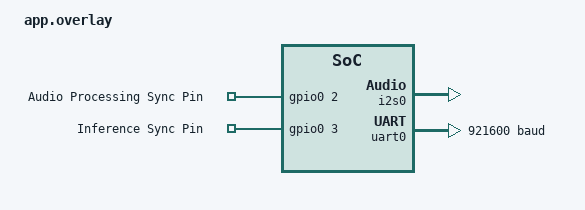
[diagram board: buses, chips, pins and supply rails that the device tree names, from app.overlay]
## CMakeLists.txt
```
# Copyright (c) 2026 Seeed Studio / Senior ML Engineer
# SPDX-License-Identifier: Apache-2.0

cmake_minimum_required(VERSION 3.20.0)

# Find Zephyr package
find_package(Zephyr REQUIRED HINTS $ENV{ZEPHYR_BASE})
project(esc50_zephyr)

# Include esp-dl path (located in /home/acar/streamable-kws/esp-dl)
if(NOT DEFINED ESPDL_PATH)
    set(ESPDL_PATH ${CMAKE_CURRENT_SOURCE_DIR}/../../../streamable-kws/esp-dl/esp-dl)
    if(NOT EXISTS ${ESPDL_PATH})
        set(ESPDL_PATH /home/acar/streamable-kws/esp-dl/esp-dl)
    endif()
endif()

if(NOT DEFINED DL_FFT_PATH)
    set(DL_FFT_PATH ${CMAKE_CURRENT_SOURCE_DIR}/../../../streamable-kws/esp-dl/tools/dl_fft)
    if(NOT EXISTS ${DL_FFT_PATH})
        set(DL_FFT_PATH /home/acar/streamable-kws/esp-dl/tools/dl_fft)
    endif()
endif()

# ============================================================
# ESP-IDF HAL Paths (for PDM support)
# ============================================================
if(NOT DEFINED ESP_HAL_PATH)
    set(ESP_HAL_PATH ${CMAKE_CURRENT_SOURCE_DIR}/../../../zephyrproject/modules/hal/espressif)
    if(NOT EXISTS ${ESP_HAL_PATH})
        set(ESP_HAL_PATH /home/acar/zephyrproject/modules/hal/espressif)
    endif()
endif()

target_include_directories(app PRIVATE
    src/compat
    ${ESPDL_PATH}/dl
    ${ESPDL_PATH}/dl/tool/include
    ${ESPDL_PATH}/dl/tensor/include
    ${ESPDL_PATH}/dl/base
    ${ESPDL_PATH}/dl/base/isa
    ${ESPDL_PATH}/dl/base/isa/tie728
    ${ESPDL_PATH}/dl/base/isa/xtensa
    ${ESPDL_PATH}/dl/math/include
    ${ESPDL_PATH}/dl/model/include
    ${ESPDL_PATH}/dl/module/include
    ${ESPDL_PATH}/fbs_loader/include
    ${ESPDL_PATH}/audio/common
    ${ESPDL_PATH}/audio/speech_features
    ${DL_FFT_PATH}
    ${DL_FFT_PATH}/base
    ${DL_FFT_PATH}/base/isa
    ${CMAKE_CURRENT_BINARY_DIR}
    src
    # ESP-IDF HAL includes - CORRECTED PATHS
    ${ESP_HAL_PATH}/components/esp_hal_i2s/include/hal
    ${ESP_HAL_PATH}/components/esp_common/include
    ${ESP_HAL_PATH}/components/driver/include
    ${ESP_HAL_PATH}/components/esp_hw_support/include
    ${ESP_HAL_PATH}/components/esp_hw_support/include/soc
    ${ESP_HAL_PATH}/components/soc/esp32s3/include
    ${ESP_HAL_PATH}/components/soc/include
    ${ESP_HAL_PATH}/components/esp_rom/include
    ${ESP_HAL_PATH}/components/esp_rom/include/esp32s3
    ${ESP_HAL_PATH}/components/esp_private/include
    ${ESP_HAL_PATH}/components/esp_hal_i2s/include
)

target_compile_definitions(app PRIVATE
    _USE_MATH_DEFINES
    _GNU_SOURCE
    M_PI=3.14159265358979323846
    # ESP-IDF definitions for HAL
    ESP_PLATFORM=1
    SOC_ESP32S3=1
    CONFIG_IDF_TARGET_ESP32S3=1
    CONFIG_SPIRAM=1
)

file(GLOB ESPDL_SRCS
    ${ESPDL_PATH}/dl/tool/src/*.cpp
    ${ESPDL_PATH}/dl/tool/isa/tie728/*.S
    ${ESPDL_PATH}/dl/tool/isa/xtensa/*.S
    ${ESPDL_PATH}/dl/tensor/src/*.cpp
    ${ESPDL_PATH}/dl/base/*.cpp
    ${ESPDL_PATH}/dl/base/isa/tie728/*.S
    ${ESPDL_PATH}/dl/base/isa/xtensa/*.S
    ${ESPDL_PATH}/dl/math/src/*.cpp
    ${ESPDL_PATH}/dl/model/src/*.cpp
    ${ESPDL_PATH}/dl/module/src/*.cpp
    ${ESPDL_PATH}/fbs_loader/src/*.cpp
    ${ESPDL_PATH}/audio/common/*.cpp
    ${ESPDL_PATH}/audio/speech_features/*.cpp
    ${DL_FFT_PATH}/*.c
    ${DL_FFT_PATH}/base/*.c
    ${DL_FFT_PATH}/base/isa/esp32s3/*.S
)

target_sources(app PRIVATE 
    src/main.cpp 
    src/audio.cpp
    src/audio_preprocessing.cpp
    src/inference.cpp
    src/compat/posix_stubs.c
    src/compat/esp_heap_caps.cpp 
    ${ESPDL_SRCS}
)

# Link ESP-IDF HAL library if available
target_link_libraries(app PRIVATE 
    ${ESPDL_PATH}/fbs_loader/lib/esp32s3/libfbs_model.a
    "-Wl,--wrap=heap_caps_malloc"
    "-Wl,--wrap=heap_caps_free"
    "-Wl,--wrap=heap_caps_realloc"
    "-Wl,--wrap=heap_caps_calloc"
    "-Wl,--wrap=heap_caps_aligned_alloc"
    "-Wl,--wrap=heap_caps_aligned_free"
    "-Wl,--wrap=heap_caps_aligned_calloc"
    "-Wl,--wrap=heap_caps_get_free_size"
    "-Wl,--wrap=heap_caps_get_largest_free_block"
    "-Wl,--wrap=heap_caps_get_allocated_size"
    "-Wl,--wrap=heap_caps_get_total_size"
    "-Wl,--wrap=heap_caps_get_minimum_free_size"
    "-Wl,--wrap=heap_caps_get_info"
    "-Wl,--wrap=heap_caps_malloc_default"
    "-Wl,--wrap=heap_caps_realloc_default"
    "-Wl,--wrap=heap_caps_malloc_prefer"
    "-Wl,--wrap=heap_caps_realloc_prefer"
    "-Wl,--wrap=heap_caps_calloc_prefer"
    "-Wl,--wrap=heap_caps_register_failed_alloc_callback"
    "-Wl,--wrap=heap_caps_malloc_extmem_enable"
    "-Wl,--wrap=heap_caps_print_heap_info"
    "-Wl,--wrap=heap_caps_check_integrity"
    "-Wl,--wrap=heap_caps_check_integrity_all"
    "-Wl,--wrap=heap_caps_check_integrity_addr"
    "-Wl,--wrap=heap_caps_dump"
    "-Wl,--wrap=heap_caps_dump_all"
    "-Wl,--wrap=malloc"
    "-Wl,--wrap=free"
    "-Wl,--wrap=calloc"
    "-Wl,--wrap=realloc"
)

# Try to link ESP-IDF HAL libraries if they exist
if(EXISTS ${ESP_HAL_PATH}/components/esp_common/lib/esp32s3/libesp_common.a)
    target_link_libraries(app PRIVATE 
        ${ESP_HAL_PATH}/components/esp_common/lib/esp32s3/libesp_common.a
    )
endif()

if(EXISTS ${ESP_HAL_PATH}/components/driver/lib/esp32s3/libdriver.a)
    target_link_libraries(app PRIVATE 
        ${ESP_HAL_PATH}/components/driver/lib/esp32s3/libdriver.a
    )
endif()

generate_inc_file_for_target(app src/model.espdl ${CMAKE_CURRENT_BINARY_DIR}/model_espdl.inc)
```

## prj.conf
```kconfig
# C++ Support
CONFIG_CPP=y
CONFIG_STD_CPP20=y
CONFIG_REQUIRES_FULL_LIBCPP=y
CONFIG_NEWLIB_LIBC=y
# FPU Support
CONFIG_FPU=y
CONFIG_FPU_SHARING=y

# ESP32-S3 PSRAM - Use PSRAM for large allocations!
CONFIG_ESP_SPIRAM=y
CONFIG_SPIRAM_MODE_OCT=y
CONFIG_ESP_SPIRAM_HEAP_SIZE=4194304

# Memory - Optimized for DRAM (64 KB Heap for Slim TCN RODATA execution)
CONFIG_HEAP_MEM_POOL_SIZE=65536
CONFIG_MAIN_STACK_SIZE=8192
CONFIG_SYSTEM_WORKQUEUE_STACK_SIZE=4096
CONFIG_IDLE_STACK_SIZE=2048
CONFIG_ISR_STACK_SIZE=4096

# Logging
CONFIG_LOG=y
CONFIG_LOG_DEFAULT_LEVEL=3
CONFIG_LOG_MODE_IMMEDIATE=y
CONFIG_LOG_BUFFER_SIZE=4096
CONFIG_SERIAL=y
CONFIG_CONSOLE=y
CONFIG_UART_CONSOLE=y

# GPIO
CONFIG_GPIO=y

# I2S
CONFIG_I2S=y
CONFIG_I2S_ESP32=y
CONFIG_I2S_ESP32_RX_BLOCK_COUNT=16
CONFIG_DMA=y
CONFIG_DMA_ESP32=y

# Ring buffer
CONFIG_RING_BUFFER_LARGE=y

# Disable unnecessary features to save RAM
CONFIG_DEBUG_THREAD_INFO=n
CONFIG_THREAD_STACK_INFO=n
CONFIG_STACK_SENTINEL=n

# Speed Optimizations (Compile with -O2)
CONFIG_SPEED_OPTIMIZATIONS=y

# Disable Bluetooth to maximize free RAM & CPU performance
CONFIG_BT=n

# CPU Clock Frequency (240 MHz Max Speed)
CONFIG_SYS_CLOCK_HW_CYCLES_PER_SEC=240000000
```

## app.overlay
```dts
/*
 * Device Tree Overlay for Seeed Studio XIAO ESP32-S3 Sense
 * I2S Microphone Pin Configuration (3-wire I2S RX Stream: BCK, SD, WS)
 */

#include <zephyr/dt-bindings/pinctrl/esp32s3-pinctrl.h>

/ {
	aliases {
		i2s-mic = &i2s0;
		sync-ap = &sync_ap_pin;
		sync-inf = &sync_inf_pin;
	};
	chosen {
		/delete-property/ zephyr,camera;
	};

	debug_pins {
		compatible = "gpio-keys";
		sync_ap_pin: sync_ap_pin {
			gpios = <&gpio0 2 GPIO_ACTIVE_HIGH>; /* GPIO2 (Pin D1) */
			label = "Audio Processing Sync Pin";
		};
		sync_inf_pin: sync_inf_pin {
			gpios = <&gpio0 3 GPIO_ACTIVE_HIGH>; /* GPIO3 (Pin D2) */
			label = "Inference Sync Pin";
		};
	};
};

&i2c1 {
	status = "disabled";
};

&lcd_cam {
	status = "disabled";
};

&lcd_cam_dvp {
	status = "disabled";
};


&pinctrl {
	i2s0_default: i2s0_default {
		group1 {
			pinmux =
				 <I2S0_I_WS_GPIO42>,
				 <I2S0_I_SD_GPIO41>;
		};
	};
};

&i2s0 {
	status = "okay";
	pinctrl-0 = <&i2s0_default>;
	pinctrl-names = "default";
};

&uart0 {
	status = "okay";
	current-speed = <921600>;
};

&cpu0 {
	clock-frequency = <160000000>;
};

&cpu1 {
	clock-frequency = <160000000>;
};
```

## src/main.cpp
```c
#include <zephyr/kernel.h>
#include <zephyr/logging/log.h>
#include <zephyr/drivers/gpio.h>
#include <cstring>
#include <cstdio>

#include "esc_config.hpp"
#include "audio.hpp"
#include "audio_preprocessing.hpp"
#include "inference.hpp"

LOG_MODULE_REGISTER(esc50_app, LOG_LEVEL_INF);

/* Built-in LED: GPIO21, active-low (LED_ON = low, LED_OFF = high) */
#define LED0_NODE DT_ALIAS(led0)
static const struct gpio_dt_spec led = GPIO_DT_SPEC_GET(LED0_NODE, gpios);

K_THREAD_STACK_DEFINE(inf_stack, 16384);
static struct k_thread inf_thread_data;

static void inf_thread_entry(void *p1, void *p2, void *p3)
{
    KWSInference *kws = (KWSInference *)p1;
    while (1) {
        k_sem_take(&kws->inf_sem, K_FOREVER);
        kws->run_inference_now();
    }
}

int main(void)
{
    LOG_INF("==================================================");
    LOG_INF("  XIAO ESP32-S3 Sense: ESC-50 50-Class Classifier (Zephyr)");
    LOG_INF("==================================================");

    /* --------------------------------------------------------
     * STARTUP BLINK: 3 fast blinks to confirm power-up and
     * firmware boot. Visible without a serial console.
     * -------------------------------------------------------- */
    if (device_is_ready(led.port)) {
        gpio_pin_configure_dt(&led, GPIO_OUTPUT_INACTIVE);
        for (int i = 0; i < 3; i++) {
            gpio_pin_set_dt(&led, 1);   /* LED ON  */
            k_sleep(K_MSEC(200));
            gpio_pin_set_dt(&led, 0);   /* LED OFF */
            k_sleep(K_MSEC(200));
        }
    }

    KWSInference kws_engine;
    if (!kws_engine.init()) {
        LOG_ERR("[FLAG: ERROR] ESC-50 Inference engine initialization failed!");
        return -1;
    }

    if (!i2s_mic_init()) {
        LOG_ERR("[FLAG: ERROR] I2S PDM Microphone initialization failed!");
        return -1;
    }

    /* Spawn background inference thread on Core 1 after I2S hardware is initialized */
    k_thread_create(&inf_thread_data, inf_stack, K_THREAD_STACK_SIZEOF(inf_stack),
                    inf_thread_entry, &kws_engine, NULL, NULL,
                    7, 0, K_NO_WAIT);

    LOG_INF("==================================================");
    LOG_INF("[FLAG: LIVE] Using real PDM microphone!");
    LOG_INF("Ready for real-time INT8 ESC-50 50-class inference!");
    LOG_INF("==================================================");

    AudioProcessor audio_processor;

    int frame_counter = 0;
    int audio_buffer_index = 0;
    int16_t audio_pool[FRAME_SHIFT_SAMPLES] = {0};
    int16_t audio_window[FRAME_LEN_SAMPLES] = {0};

    while (1) {
        void *mem_block = nullptr;
        size_t block_size = 0;
        int ret = i2s_mic_read_block(&mem_block, &block_size);

        if (ret == 0 && mem_block != nullptr && block_size == I2S_BLOCK_SIZE) {
            uint8_t *byte_ptr = (uint8_t *)mem_block;
            
            for (int i = 0; i < SAMPLES_PER_BLOCK; i++) {
                int16_t raw_l = (int16_t)(byte_ptr[i * 8 + 2] | (byte_ptr[i * 8 + 3] << 8));
                int16_t raw_r = (int16_t)(byte_ptr[i * 8 + 6] | (byte_ptr[i * 8 + 7] << 8));
                
                int16_t clean_sample = audio_processor.process_sample_pair(raw_l, raw_r);

#if STREAM_RAW_PCM_MODE > 0
                int16_t stream_val = (STREAM_RAW_PCM_MODE == 1) ? raw_l : clean_sample;
                putchar(stream_val & 0xFF);
                putchar((stream_val >> 8) & 0xFF);
#else
                audio_pool[audio_buffer_index++] = clean_sample;

                if (audio_buffer_index >= FRAME_SHIFT_SAMPLES) {
                    audio_buffer_index = 0;

                    // Shift window
                    memmove(audio_window, audio_window + FRAME_SHIFT_SAMPLES, 
                            (FRAME_LEN_SAMPLES - FRAME_SHIFT_SAMPLES) * sizeof(int16_t));
                    
                    memcpy(audio_window + (FRAME_LEN_SAMPLES - FRAME_SHIFT_SAMPLES), 
                           audio_pool, FRAME_SHIFT_SAMPLES * sizeof(int16_t));

                    bool log_details = false;

                    kws_engine.process_audio_window(audio_window, frame_counter, log_details);

                    frame_counter++;
                    if (frame_counter > 1000000) frame_counter = 0;
                }
#endif
            }
#if STREAM_RAW_PCM_MODE == 0
            // audio_processor.check_and_report_diagnostics();
#endif
            i2s_mic_free_block(mem_block);
        } else {
            if (mem_block != nullptr) {
                i2s_mic_free_block(mem_block);
            }
            k_sleep(K_MSEC(1));
        }
    }
    return 0;
}
```

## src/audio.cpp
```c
/*
 * Copyright (c) 2026 Seeed Studio / Senior ML Engineer
 * SPDX-License-Identifier: Apache-2.0
 * 
 * audio_i2s.cpp - I2S driver wrapper for the PDM microphone on the Xiao ESP32-S3.
 * Configures the ESP32-S3 I2S peripheral in PDM RX mode, manages the DMA
 * memory slabs, and provides automatic recovery from audio stream underflows.
 */

#include "audio.hpp"
#include "esc_config.hpp"

#include <zephyr/kernel.h>
#include <zephyr/logging/log.h>
#include <zephyr/drivers/i2s.h>
#include <zephyr/drivers/gpio.h>

/* ESP32-S3 direct hardware register access definitions */
#include <soc/i2s_struct.h>
#include <soc/i2s_reg.h>

LOG_MODULE_DECLARE(esc50_app, LOG_LEVEL_INF);

/* 
 * Define static memory slab pool for I2S DMA.
 * Allocates 32 blocks of I2S_BLOCK_SIZE bytes (32 KB total DMA buffer).
 */
K_MEM_SLAB_DEFINE_STATIC(rx_mem_slab, I2S_BLOCK_SIZE, 32, 8);

static const struct device *i2s_dev = nullptr;

/*
 * apply_pdm_regs: Directly configures the ESP32-S3 I2S hardware registers
 *                 to enable PDM-to-PCM demodulation and SINC decimation filter.
 */
static void apply_pdm_regs(void)
{
    I2S0.rx_conf.rx_pdm_en = 1;              // Enable PDM RX channel
    I2S0.rx_conf.rx_pdm2pcm_en = 1;          // Enable hardware PDM-to-PCM demodulator
    I2S0.rx_conf.rx_pdm_sinc_dsr_16_en = 1;  // Set oversampling rate to 16
    I2S0.rx_conf.rx_tdm_en = 0;              // Disable TDM mode
    I2S0.rx_conf.rx_mono = 0;                 // Disable Mono mode (read stereo)
    I2S0.rx_conf.rx_update = 1;              // Apply changes immediately
}

/*
 * full_i2s_reset: Performs a full hardware reset on the I2S peripheral,
 *                 clears the DMA queue, and restarts the audio capture.
 */
static void full_i2s_reset(void)
{
    LOG_WRN("Full I2S reset...");
    
    /* Stop DMA capture */
    i2s_trigger(i2s_dev, I2S_DIR_RX, I2S_TRIGGER_DROP);
    k_sleep(K_MSEC(10));
    
    /* Reset RX unit and FIFO */
    I2S0.rx_conf.rx_reset = 1;
    I2S0.rx_conf.rx_fifo_reset = 1;
    k_sleep(K_MSEC(10));
    I2S0.rx_conf.rx_reset = 0;
    I2S0.rx_conf.rx_fifo_reset = 0;
    
    /* Flush the DMA queue and free all allocated blocks */
    void *dummy;
    size_t dummy_size;
    while (i2s_read(i2s_dev, &dummy, &dummy_size) == 0 && dummy != NULL) {
        k_mem_slab_free(&rx_mem_slab, dummy);
    }
    
    apply_pdm_regs();
    
    /* Restart DMA capture */
    if (i2s_trigger(i2s_dev, I2S_DIR_RX, I2S_TRIGGER_START) != 0) {
        LOG_ERR("Failed to start I2S after reset!");
        return;
    }
    
    LOG_INF("I2S reset complete");
}

/*
 * i2s_mic_init: Gets the I2S device from the device tree, configures 
 *               the sampling rate, registers PDM settings, and starts capturing.
 */
bool i2s_mic_init(void)
{
    LOG_INF("[FLAG: STAGE_0_START] Initializing I2S PDM Microphone...");

    /* Get I2S device node from DTS */
    i2s_dev = DEVICE_DT_GET(DT_NODELABEL(i2s0));
    if (!device_is_ready(i2s_dev)) {
        LOG_ERR("[FLAG: ERROR] I2S device not ready!");
        return false;
    }
    LOG_INF("I2S device found: %s", i2s_dev->name);

    /* Setup I2S configuration parameters */
    struct i2s_config i2s_cfg = {
        .word_size = 16,
        .channels = 2,
        .format = I2S_FMT_DATA_FORMAT_I2S,
        .options = I2S_OPT_BIT_CLK_MASTER | I2S_OPT_FRAME_CLK_MASTER,
        .frame_clk_freq = SAMPLE_RATE * 8, // Set decimation clock frequency
        .mem_slab = &rx_mem_slab,
        .block_size = I2S_BLOCK_SIZE,
        .timeout = 1000,
    };

    if (i2s_configure(i2s_dev, I2S_DIR_RX, &i2s_cfg) != 0) {
        LOG_ERR("[FLAG: ERROR] Failed to configure I2S!");
        return false;
    }

    apply_pdm_regs();

    /* Trigger the I2S capture to start filling memory blocks via DMA */
    if (i2s_trigger(i2s_dev, I2S_DIR_RX, I2S_TRIGGER_START) != 0) {
        LOG_ERR("[FLAG: ERROR] Failed to start I2S!");
        return false;
    }

    k_sleep(K_MSEC(100));
    LOG_INF("[FLAG: SUCCESS] I2S started with PDM RX enabled!");
    return true;
}

/*
 * i2s_mic_read_block: Reads a processed PCM audio block from the DMA queue.
 *                     If reading fails (e.g. queue overflow or buffer underflow),
 *                     it triggers an automatic hardware reset to recover.
 */
int i2s_mic_read_block(void **mem_block, size_t *block_size)
{
    if (!i2s_dev) {
        return -1;
    }

    /* Force PDM register settings prior to reading to avoid hardware drift */
    apply_pdm_regs();

    int ret = i2s_read(i2s_dev, mem_block, block_size);
    
    /* Handle read failure or missing buffer pointers */
    if (ret != 0 || mem_block == NULL) {
        static int error_count = 0;
        error_count++;
        LOG_WRN("I2S read issue: ret=%d, mem_block=%p (count: %d)", ret, mem_block, error_count);
        
        /* Stop and reset the I2S capture pipeline */
        i2s_trigger(i2s_dev, I2S_DIR_RX, I2S_TRIGGER_DROP);
        k_sleep(K_MSEC(10));
        
        I2S0.rx_conf.rx_reset = 1;
        I2S0.rx_conf.rx_fifo_reset = 1;
        k_sleep(K_MSEC(10));
        I2S0.rx_conf.rx_reset = 0;
        I2S0.rx_conf.rx_fifo_reset = 0;
        
        apply_pdm_regs();
        
        if (i2s_trigger(i2s_dev, I2S_DIR_RX, I2S_TRIGGER_START) != 0) {
            LOG_ERR("Failed to start I2S after reset!");
            return -1;
        }
        
        /* Retry the read after resetting the pipeline */
        ret = i2s_read(i2s_dev, mem_block, block_size);
        if (ret != 0 || mem_block == NULL) {
            LOG_ERR("I2S still failing after reset! ret=%d", ret);
            return ret;
        }
        
        LOG_INF("I2S recovered successfully!");
    }
    
    return 0;
}

/*
 * i2s_mic_free_block: Frees the processed memory block back to the mem slab pool.
 */
void i2s_mic_free_block(void *mem_block)
{
    if (mem_block) {
        k_mem_slab_free(&rx_mem_slab, mem_block);
    }
}
```

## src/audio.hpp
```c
/*
 * Copyright (c) 2026 Seeed Studio / Senior ML Engineer
 * SPDX-License-Identifier: Apache-2.0
 */

#ifndef AUDIO_HPP
#define AUDIO_HPP

#include <cstddef>

/**
 * @brief Initialize the I2S PDM microphone device and memory slabs.
 * @return true if initialization succeeded, false otherwise.
 */
bool i2s_mic_init();

/**
 * @brief Read an audio block from the I2S microphone.
 * @param mem_block Output pointer to received memory block.
 * @param block_size Output pointer to size of received block.
 * @return 0 on success, negative error code on failure.
 */
int i2s_mic_read_block(void **mem_block, size_t *block_size);

/**
 * @brief Free a previously read I2S memory block.
 * @param mem_block Memory block to free.
 */
void i2s_mic_free_block(void *mem_block);

#endif // AUDIO_HPP
```

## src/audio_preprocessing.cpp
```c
/*
 * Copyright (c) 2026 Seeed Studio / Senior ML Engineer
 * SPDX-License-Identifier: Apache-2.0
 * 
 * audio_preprocessing.cpp - Real-time audio processing pipeline.
 * Performs gain scaling, soft-limiting, DC blocking high-pass filtering,
 * automatic microphone channel selection, and continuous diagnostic reporting.
 */

#include "audio_preprocessing.hpp"
#include "esc_config.hpp"

#include <zephyr/logging/log.h>
#include <cmath>
#include <algorithm>

LOG_MODULE_DECLARE(esc50_app, LOG_LEVEL_INF);

/*
 * Constructor: Initializes filter state variables and resets diagnostic counters.
 */
AudioProcessor::AudioProcessor()
    : use_right_channel(false), is_crossfading(false), crossfade_count(0), target_right_channel(false),
      hpf_x1_l(0.0f), hpf_y1_l(0.0f), hpf_x1_r(0.0f), hpf_y1_r(0.0f),
      lpf1_x1_l(0.0f), lpf1_x2_l(0.0f), lpf1_y1_l(0.0f), lpf1_y2_l(0.0f),
      lpf1_x1_r(0.0f), lpf1_x2_r(0.0f), lpf1_y1_r(0.0f), lpf1_y2_r(0.0f),
      lpf2_x1_l(0.0f), lpf2_x2_l(0.0f), lpf2_y1_l(0.0f), lpf2_y2_l(0.0f),
      lpf2_x1_r(0.0f), lpf2_x2_r(0.0f), lpf2_y1_r(0.0f), lpf2_y2_r(0.0f),
      prev_sample_l(0), prev_sample_r(0)
{
    reset_diagnostics();
}

/*
 * reset_diagnostics: Resets all running statistical registers used for logging.
 */
void AudioProcessor::reset_diagnostics()
{
    raw_sum_sq_l = 0; raw_sum_sq_r = 0;
    diag_sum_sq_l = 0; diag_sum_sq_r = 0;
    diag_sum_l = 0; diag_sum_r = 0;
    diag_min_l = 32767; diag_max_l = -32768;
    diag_min_r = 32767; diag_max_r = -32768;
    raw_min_l = 32767; raw_max_l = -32768;
    raw_min_r = 32767; raw_max_r = -32768;
    diag_zcr_l = 0; diag_zcr_r = 0;
    diag_clip_l = 0; diag_clip_r = 0;
    diag_sample_count = 0;
}

/*
 * process_sample_pair: Processes raw stereo PDM microphone samples (Left and Right).
 * 
 * Execution Steps:
 * 1. Accumulate raw input signal stats.
 * 2. Apply a Soft Limiter with a 0.35 gain scale to protect against digital clipping.
 * 3. Run a DC-blocking High-Pass Filter (cut-off ~80Hz) to filter out sub-bass rumble/DC offset.
 * 4. Accumulate clean signal stats (ZCR, peaks, sum of squares).
 * 5. Auto-Channel Lock: Locks on to the channel with higher speech energy after 1 second.
 * 6. Return the chosen channel's sample.
 */
int16_t AudioProcessor::process_sample_pair(int16_t raw_l, int16_t raw_r)
{
    raw_sum_sq_l += (int32_t)raw_l * (int32_t)raw_l;
    raw_sum_sq_r += (int32_t)raw_r * (int32_t)raw_r;
    
    if (raw_l < raw_min_l) raw_min_l = raw_l;
    if (raw_l > raw_max_l) raw_max_l = raw_l;
    if (raw_r < raw_min_r) raw_min_r = raw_r;
    if (raw_r > raw_max_r) raw_max_r = raw_r;

    // --- 1. Soft Limiter (Input stage) to prevent clipping / state overflow ---
    const float input_gain = 1.5f; 
    const float in_limit = 24000.0f; // Soft limiting headroom
    
    // Left Channel Input & Limit
    float in_l = (float)raw_l * input_gain;
    if (in_l > in_limit) {
        in_l = in_limit + (in_l - in_limit) / (1.0f + (in_l - in_limit) / (32767.0f - in_limit));
    } else if (in_l < -in_limit) {
        in_l = -in_limit + (in_l + in_limit) / (1.0f - (in_l + in_limit) / (32768.0f - in_limit));
    }

    // --- 2. DC Blocking HPF ---
    const float hpf_r = 0.99f; // ~25 Hz sub-bass cutoff (preserves coughing/speech fundamentals)
    float hpf_out_l = in_l - hpf_x1_l + hpf_r * hpf_y1_l;
    hpf_x1_l = in_l; hpf_y1_l = hpf_out_l;
 
    // --- 3. LPF (Bypassed: using hardware decimation) ---
    float out_l = hpf_out_l;
 
    if (out_l > 32767.0f) out_l = 32767.0f; else if (out_l < -32768.0f) out_l = -32768.0f;
    int16_t sample_l = (int16_t)out_l;
 
    // --- Right Channel Input & Limit ---
    float in_r = (float)raw_r * input_gain;
    if (in_r > in_limit) {
        in_r = in_limit + (in_r - in_limit) / (1.0f + (in_r - in_limit) / (32767.0f - in_limit));
    } else if (in_r < -in_limit) {
        in_r = -in_limit + (in_r + in_limit) / (1.0f - (in_r + in_limit) / (32768.0f - in_limit));
    }

    // DC Blocking HPF for Right Channel
    float hpf_out_r = in_r - hpf_x1_r + hpf_r * hpf_y1_r;
    hpf_x1_r = in_r; hpf_y1_r = hpf_out_r;
 
    // LPF (Bypassed: using hardware decimation) for Right Channel
    float out_r = hpf_out_r;
 
    if (out_r > 32767.0f) out_r = 32767.0f; else if (out_r < -32768.0f) out_r = -32768.0f;
    int16_t sample_r = (int16_t)out_r;
    
    // --- Lightweight O(1) Diagnostics Accumulation on Clean Signal ---
    diag_sum_l += sample_l;
    diag_sum_r += sample_r;
    diag_sum_sq_l += (int32_t)sample_l * (int32_t)sample_l;
    diag_sum_sq_r += (int32_t)sample_r * (int32_t)sample_r;
    
    if (sample_l < diag_min_l) diag_min_l = sample_l;
    if (sample_l > diag_max_l) diag_max_l = sample_l;
    if (sample_r < diag_min_r) diag_min_r = sample_r;
    if (sample_r > diag_max_r) diag_max_r = sample_r;
    
    // Track Zero-Crossing Rate (ZCR) for both channels to analyze hiss/high-frequency noise
    if ((sample_l >= 0 && prev_sample_l < 0) || (sample_l < 0 && prev_sample_l >= 0)) diag_zcr_l++;
    if ((sample_r >= 0 && prev_sample_r < 0) || (sample_r < 0 && prev_sample_r >= 0)) diag_zcr_r++;
    prev_sample_l = sample_l;
    prev_sample_r = sample_r;
    
    // Accumulate clipping occurrences
    if (sample_l <= -32000 || sample_l >= 32000) diag_clip_l++;
    if (sample_r <= -32000 || sample_r >= 32000) diag_clip_r++;
    
    diag_sample_count++;
    
    // Dynamically pick whichever channel contains active microphone signal (eliminates dead/floating channel static)
    int16_t active_sample = (abs(sample_l) >= abs(sample_r)) ? sample_l : sample_r;

    return active_sample;
}

/*
 * check_and_report_diagnostics: Prints a diagnostic report summarizing raw & post-filtered
 *                              signal properties (RMS, ZCR, clipping) every 10 seconds.
 */
void AudioProcessor::check_and_report_diagnostics()
{
    const int diag_report_interval = SAMPLE_RATE * 10;
    if (diag_sample_count >= diag_report_interval) {
        float raw_rms_l = sqrtf((float)raw_sum_sq_l / diag_sample_count);
        float raw_rms_r = sqrtf((float)raw_sum_sq_r / diag_sample_count);

        float mean_l = (float)diag_sum_l / diag_sample_count;
        float mean_r = (float)diag_sum_r / diag_sample_count;
        
        float var_l = ((float)diag_sum_sq_l / diag_sample_count) - (mean_l * mean_l);
        float var_r = ((float)diag_sum_sq_r / diag_sample_count) - (mean_r * mean_r);
        float rms_l = sqrtf(std::max(0.0f, var_l));
        float rms_r = sqrtf(std::max(0.0f, var_r));
        
        float dbfs_l = 20.0f * log10f(std::max(1.0f, rms_l) / 32768.0f);
        float dbfs_r = 20.0f * log10f(std::max(1.0f, rms_r) / 32768.0f);
        
        float zcr_pct_l = (100.0f * diag_zcr_l) / diag_sample_count;
        float zcr_pct_r = (100.0f * diag_zcr_r) / diag_sample_count;
        
        LOG_INF("================== AUDIO DIAGNOSIS REPORT (POST-FILTER) ==================");
        LOG_INF("Filter Active: DC Blocking HPF + 0.30x Input Gain + Limiter + 6kHz LPF");
        LOG_INF("Samples Analyzed: %d (~2.0 sec)", diag_sample_count);
        LOG_INF("Left  Ch (CH0) | Raw RMS: %6.1f, Raw Peak: [%6d, %6d] -> Clean RMS: %6.1f (%5.1f dBFS) | Peak: [%d, %d] | ZCR: %4.1f%% | Clips: %d",
                (double)raw_rms_l, raw_min_l, raw_max_l, (double)rms_l, (double)dbfs_l, diag_min_l, diag_max_l, (double)zcr_pct_l, diag_clip_l);
        LOG_INF("Right Ch (CH1) | Raw RMS: %6.1f, Raw Peak: [%6d, %6d] -> Clean RMS: %6.1f (%5.1f dBFS) | Peak: [%d, %d] | ZCR: %4.1f%% | Clips: %d",
                (double)raw_rms_r, raw_min_r, raw_max_r, (double)rms_r, (double)dbfs_r, diag_min_r, diag_max_r, (double)zcr_pct_r, diag_clip_r);
        
        if (rms_l < 10.0f && rms_r < 10.0f) {
            LOG_WRN("[DIAGNOSIS] Both channels have near-zero RMS. Mic may be disconnected, muted, or I2S clock mismatch!");
        } else if (rms_l > 500.0f && rms_r < 50.0f) {
            LOG_INF("[DIAGNOSIS] Active audio detected on LEFT channel (CH0).");
        } else if (rms_r > 500.0f && rms_l < 50.0f) {
            LOG_WRN("[DIAGNOSIS] Active audio is on RIGHT channel (CH1), but ESC50 is reading LEFT! Check mic channel strapping.");
        }
        
        if (zcr_pct_l > 35.0f || zcr_pct_r > 35.0f) {
            LOG_WRN("[DIAGNOSIS] High Zero-Crossing Rate (>35%%) detected. Indicates high-frequency white noise or clock hiss!");
        } else {
            LOG_INF("[DIAGNOSIS] ZCR is normal (<35%%). PDM high-frequency hiss successfully suppressed!");
        }
        if (diag_clip_l > 10 || diag_clip_r > 10) {
            LOG_WRN("[DIAGNOSIS] Signal clipping detected! Mic gain or PDM scaling is too high.");
        }
        LOG_INF("==========================================================================");
        
        reset_diagnostics();
    }
}
```

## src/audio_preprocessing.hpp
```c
/*
 * Copyright (c) 2026 Seeed Studio / Senior ML Engineer
 * SPDX-License-Identifier: Apache-2.0
 */

#ifndef AUDIO_PREPROCESSING_HPP
#define AUDIO_PREPROCESSING_HPP

#include <cstdint>

class AudioProcessor {
public:
    AudioProcessor();

    /**
     * @brief Process a raw stereo sample pair from PDM mic: applies DC-blocking HPF,
     * Soft Limiter, updates diagnostics, dynamically selects active channel,
     * and returns the filtered sample of the active channel.
     * @param raw_l Raw left channel sample
     * @param raw_r Raw right channel sample
     * @return Filtered active channel sample
     */
    int16_t process_sample_pair(int16_t raw_l, int16_t raw_r);

    /**
     * @brief Check if diagnostic reporting threshold is reached and output diagnosis report if needed.
     */
    void check_and_report_diagnostics();

    /**
     * @brief Check whether the right channel (CH1) is currently active.
     */
    bool is_using_right_channel() const { return use_right_channel; }

private:
    void reset_diagnostics();

    bool use_right_channel;
    bool is_crossfading;
    int crossfade_count;
    bool target_right_channel;

    // Filter states
    float hpf_x1_l, hpf_y1_l;
    float hpf_x1_r, hpf_y1_r;
    float lpf1_x1_l, lpf1_x2_l, lpf1_y1_l, lpf1_y2_l;
    float lpf1_x1_r, lpf1_x2_r, lpf1_y1_r, lpf1_y2_r;
    float lpf2_x1_l, lpf2_x2_l, lpf2_y1_l, lpf2_y2_l;
    float lpf2_x1_r, lpf2_x2_r, lpf2_y1_r, lpf2_y2_r;

    // Diagnostics accumulators
    uint64_t diag_sum_sq_l, diag_sum_sq_r;
    uint64_t raw_sum_sq_l, raw_sum_sq_r;
    int64_t diag_sum_l, diag_sum_r;
    int16_t diag_min_l, diag_max_l;
    int16_t diag_min_r, diag_max_r;
    int16_t raw_min_l, raw_max_l;
    int16_t raw_min_r, raw_max_r;
    int diag_zcr_l, diag_zcr_r;
    int diag_clip_l, diag_clip_r;
    int16_t prev_sample_l, prev_sample_r;
    int diag_sample_count;
};

#endif // AUDIO_PREPROCESSING_HPP
```

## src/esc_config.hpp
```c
/*
 * Copyright (c) 2026 Seeed Studio / Senior ML Engineer
 * SPDX-License-Identifier: Apache-2.0
 */

#ifndef ESC_CONFIG_HPP
#define ESC_CONFIG_HPP

#ifdef __cplusplus
#include <cstddef>
#include <cstdint>
#else
#include <stddef.h>
#include <stdint.h>
#endif

#define SAMPLE_RATE 16000
#define FRAME_LEN_SAMPLES 512
#define FRAME_SHIFT_SAMPLES 256
#define NUM_MEL_BINS 52
#define TIME_FRAMES 313

#define I2S_BLOCK_SIZE 1024
#define SAMPLES_PER_BLOCK 128

#define NUM_CLASSES 50
#define CONFIDENCE_THRESHOLD 0.30f          // ESC-50 confidence threshold (40% for 50-class split)
#define CONFIDENCE_MARGIN 0.05f             // Minimum margin over second best class (10%)
#define COOLDOWN_FRAMES 0                  // Cooldown frames after detection
#define INFERENCE_STRIDE 10
#define VOICE_ACTIVITY_RMS_THRESHOLD 100.0f   // Energy squelch: skip model run if RMS < threshold

// ============================================================================
// MULTI-DEVICE CONFIGURATION FOR LATE FUSION
// Set DEVICE_ID to 1 for Device 1 (XIAO_SENSE_BLE_1)
// Set DEVICE_ID to 2 for Device 2 (XIAO_SENSE_BLE_2)
// ============================================================================
#ifndef DEVICE_ID
#define DEVICE_ID 1
#endif

#if DEVICE_ID == 2
#define CONFIG_CUSTOM_DEVICE_NAME "XIAO_SENSE_BLE_2"
#else
#define CONFIG_CUSTOM_DEVICE_NAME "XIAO_SENSE_BLE_1"
#endif

// ============================================================================
// AUDIO STREAMING TEST MODE (For Audacity Analysis via record_to_wav.py)
// ============================================================================
// 0: Normal Inference Mode (ASCII serial logs enabled)
// 1: Stream PRE-FILTER Raw PCM over Serial (Before DC-Block HPF & Butterworth LPF)
// 2: Stream POST-FILTER Clean PCM over Serial (After DC-Block HPF & Butterworth LPF)
#define STREAM_RAW_PCM_MODE 0

#endif // ESC_CONFIG_HPP
```

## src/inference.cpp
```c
/*
 * Copyright (c) 2026 Seeed Studio / Senior ML Engineer
 * SPDX-License-Identifier: Apache-2.0
 */

#include "inference.hpp"
#include "esc_config.hpp"
#include "compat/esp_heap_caps.h"

#include <zephyr/kernel.h>
#include <zephyr/logging/log.h>
#include <zephyr/drivers/gpio.h>
#include <cstring>
#include <cmath>
#include <algorithm>

LOG_MODULE_DECLARE(esc50_app, LOG_LEVEL_INF);

/* Otii Sync GPIO Specifications */
#define SYNC_AP_NODE DT_ALIAS(sync_ap)
#define SYNC_INF_NODE DT_ALIAS(sync_inf)

static const struct gpio_dt_spec sync_ap = GPIO_DT_SPEC_GET(SYNC_AP_NODE, gpios);
static const struct gpio_dt_spec sync_inf = GPIO_DT_SPEC_GET(SYNC_INF_NODE, gpios);

static const char *CLASS_LABELS[50] = {
    "airplane", "breathing", "brushing_teeth", "can_opening", "car_horn",
    "cat", "chainsaw", "chirping_birds", "church_bells", "clapping",
    "clock_alarm", "clock_tick", "coughing", "cow", "crackling_fire",
    "crickets", "crow", "crying_baby", "dog", "door_wood_creaks",
    "door_wood_knock", "drinking_sipping", "engine", "fireworks", "footsteps",
    "frog", "glass_breaking", "hand_saw", "helicopter", "hen",
    "insects", "keyboard_typing", "laughing", "mouse_click", "pig",
    "pouring_water", "rain", "rooster", "sea_waves", "sheep",
    "siren", "sneezing", "snoring", "thunderstorm", "toilet_flush",
    "train", "vacuum_cleaner", "washing_machine", "water_drops", "wind"
};

static const float CLASS_THRESHOLDS[4] = {
    0.97f, // go (voiced vowel, high confidence)
    0.94f, // stop (sibilant start, lower confidence on mic)
    0.94f, // left (sibilant/fricative end, lower confidence on mic)
    0.96f  // right (voiced diphthong, high confidence)
};

static const int CLASS_DEBOUNCE_THRESHOLDS[4] = {
    2, // go (requires 4 consecutive frames to prevent false triggers)
    2, // stop (requires 3 consecutive frames)
    2, // left (requires 4 consecutive frames)
    2  // right (requires 4 consecutive frames)
};

static const unsigned char model_espdl_bin[] __attribute__((aligned(16))) = {
#include "model_espdl.inc"
};

KWSInference::KWSInference()
    : model(nullptr), fbank(nullptr), input_tensor(nullptr), output_tensor(nullptr),
      sliding_window_buf(nullptr), normalized_buf(nullptr), cooldown_counter(0),
      last_detected_class(-1), consecutive_count(0), dropout_count(0),
      last_ap_start(0), last_ap_end(0), last_ap_time_ms(0.0),
      last_inf_start(0), last_inf_end(0), last_inf_time_ms(0.0)
{
}

KWSInference::~KWSInference()
{
    if (model) delete model;
    if (fbank) delete fbank;
    if (sliding_window_buf) heap_caps_free(sliding_window_buf);
    if (normalized_buf) heap_caps_free(normalized_buf);
}

void KWSInference::compute_softmax(const float *logits, float *probs, int len)
{
    float max_logit = logits[0];
    for (int i = 1; i < len; i++) {
        if (logits[i] > max_logit) {
            max_logit = logits[i];
        }
    }

    float sum_exp = 0.0f;
    for (int i = 0; i < len; i++) {
        probs[i] = expf(logits[i] - max_logit);
        sum_exp += probs[i];
    }
    for (int i = 0; i < len; i++) {
        probs[i] /= sum_exp;
    }
}

bool KWSInference::init()
{
    LOG_INF("[FLAG: STAGE_0_START] Loading Model from Flash...");
    LOG_INF("Model binary at: %p (size: %zu bytes)", 
            (void *)model_espdl_bin, sizeof(model_espdl_bin));
    
    /*
     * Model Profile Selection:
     * - Profile 7 (Dense GRU): Requires param_copy=true for recurrent tensor allocation.
     * - Profile 8 (Slim TCN): Uses param_copy=false to execute directly from Flash RODATA.
     */
    #define ESP_PROFILE_SLIM_TCN  0
    #define ESP_PROFILE_DENSE_GRU 1

    #define ACTIVE_ESP_PROFILE    ESP_PROFILE_SLIM_TCN

    #if (ACTIVE_ESP_PROFILE == ESP_PROFILE_DENSE_GRU)
        constexpr bool kParamCopy = true;
    #else
        constexpr bool kParamCopy = false;
    #endif

    model = new dl::Model((const char *)model_espdl_bin, 
                          fbs::MODEL_LOCATION_IN_FLASH_RODATA,
                          0,
                          dl::MEMORY_MANAGER_GREEDY,
                          nullptr,
                          kParamCopy);

    if (model == nullptr) {
        LOG_ERR("[FLAG: ERROR] Failed to initialize dl::Model!");
        return false;
    }

    LOG_INF("[FLAG: SUCCESS] Model initialized successfully!");

    auto inputs = model->get_inputs();
    auto outputs = model->get_outputs();
    
    if (inputs.empty() || outputs.empty()) {
        LOG_ERR("[FLAG: ERROR] Model has no inputs or outputs!");
        return false;
    }
    
    LOG_INF("--- Model Inputs ---");
    for (auto const& [name, tensor] : inputs) {
        std::string shape_str = "";
        for (int d : tensor->shape) shape_str += std::to_string(d) + " ";
        LOG_INF("  Input '%s': shape=[ %s] (bytes: %d)", name.c_str(), shape_str.c_str(), tensor->get_bytes());
    }
    
    // Default to first input, which should be the spectrogram
    input_tensor = inputs.begin()->second;

    LOG_INF("--- Model Outputs ---");
    output_tensor = nullptr;
    for (auto const& [name, tensor] : outputs) {
        std::string shape_str = "";
        for (int d : tensor->shape) shape_str += std::to_string(d) + " ";
        LOG_INF("  Output '%s': shape=[ %s] (bytes: %d)", name.c_str(), shape_str.c_str(), tensor->get_bytes());
        
        // Calculate total elements in this output tensor
        int elements = 1;
        for (int d : tensor->shape) elements *= d;
        
        // The logits tensor must have exactly NUM_CLASSES elements (50)
        if (elements == NUM_CLASSES) {
            output_tensor = tensor;
            LOG_INF("  -> Selected '%s' as the active logits output tensor", name.c_str());
        }
    }

    if (output_tensor == nullptr) {
        LOG_WRN("[FLAG: WARNING] No output tensor with %d elements found! Defaulting to first output.", NUM_CLASSES);
        output_tensor = outputs.begin()->second;
    }

    // Verify input/output dimension sizes (Batch=1, Freq=52, Time=313)
    if (input_tensor->shape[0] != 1 || input_tensor->shape[1] != NUM_MEL_BINS || input_tensor->shape[2] != TIME_FRAMES) {
        LOG_ERR("[FLAG: ERROR] Input tensor shape mismatch! Expected [1, %d, %d], got [%d, %d, %d]", 
                NUM_MEL_BINS, TIME_FRAMES, input_tensor->shape[0], input_tensor->shape[1], input_tensor->shape[2]);
        return false;
    }

    if (output_tensor->shape[0] != 1 || output_tensor->shape[1] != NUM_CLASSES) {
        LOG_ERR("[FLAG: ERROR] Output tensor shape mismatch! Expected [1, %d], got [%d, %d]", 
                NUM_CLASSES, output_tensor->shape[0], output_tensor->shape[1]);
        return false;
    }

    LOG_INF("[FLAG: STAGE_0_START] Initializing Mel Filterbank...");
    dl::audio::SpeechFeatureConfig fbank_cfg;
    fbank_cfg.sample_rate = SAMPLE_RATE;       // 16000
    fbank_cfg.frame_length = 32;               // 32 ms window (512 samples at 16kHz)
    fbank_cfg.frame_shift = 16;                // 16 ms step (256 samples at 16kHz)
    fbank_cfg.num_mel_bins = NUM_MEL_BINS;     // 52 mel bins
    fbank_cfg.low_freq = 0.0f;                 // 0.0 Hz (matches PyTorch's f_min = 0.0)
    fbank_cfg.use_log_fbank = 2;               // logf(x + epsilon)
    fbank_cfg.log_epsilon = 1e-10f;
    fbank_cfg.preemphasis = 0.0f;              // No preemphasis
    fbank_cfg.remove_dc_offset = true;         // Remove DC
    fbank_cfg.window_type = dl::audio::WinType::HANN;

    fbank = new dl::audio::Fbank(fbank_cfg);
    if (fbank == nullptr) {
        LOG_ERR("[FLAG: ERROR] Failed to initialize dl::audio::Fbank!");
        return false;
    }
    LOG_INF("[FLAG: SUCCESS] Fbank initialized successfully!");

    sliding_window_buf = (float *)heap_caps_malloc(
        NUM_MEL_BINS * TIME_FRAMES * sizeof(float), MALLOC_CAP_SPIRAM);
    
    if (!sliding_window_buf) {
        LOG_ERR("[FLAG: ERROR] Failed to allocate sliding window buffer in PSRAM!");
        return false;
    }
    memset(sliding_window_buf, 0, NUM_MEL_BINS * TIME_FRAMES * sizeof(float));
    LOG_INF("[FLAG: SUCCESS] Sliding window buffer allocated and zero-initialized in PSRAM");

    normalized_buf = (float *)heap_caps_malloc(
        NUM_MEL_BINS * TIME_FRAMES * sizeof(float), MALLOC_CAP_SPIRAM);
    if (!normalized_buf) {
        LOG_ERR("[FLAG: ERROR] Failed to allocate normalized buffer in PSRAM!");
        heap_caps_free(sliding_window_buf);
        sliding_window_buf = nullptr;
        return false;
    }
    memset(normalized_buf, 0, NUM_MEL_BINS * TIME_FRAMES * sizeof(float));
    LOG_INF("[FLAG: SUCCESS] Normalized buffer allocated and zero-initialized in PSRAM");
    LOG_INF("[FLAG: SUCCESS] All buffers allocated successfully!");
    
    /* Initialize Otii Sync GPIOs as output, inactive by default */
    if (device_is_ready(sync_ap.port)) {
        gpio_pin_configure_dt(&sync_ap, GPIO_OUTPUT_INACTIVE);
        LOG_INF("[FLAG: SUCCESS] Audio Processing Sync GPIO initialized on Pin D1 (GPIO2)");
    } else {
        LOG_WRN("[FLAG: WARNING] Audio Processing Sync GPIO device not ready");
    }

    if (device_is_ready(sync_inf.port)) {
        gpio_pin_configure_dt(&sync_inf, GPIO_OUTPUT_INACTIVE);
        LOG_INF("[FLAG: SUCCESS] Inference Sync GPIO initialized on Pin D2 (GPIO3)");
    } else {
        LOG_WRN("[FLAG: WARNING] Inference Sync GPIO device not ready");
    }

    k_sem_init(&inf_sem, 0, 1);

    return true;
}

void KWSInference::process_audio_window(const int16_t *audio_window, int frame_counter, bool log_details)
{
    gpio_pin_set_dt(&sync_ap, 1); /* Set AP pin High */
    last_ap_start = k_cycle_get_32();
    float mel_frame_out[NUM_MEL_BINS] = {0};
    fbank->process_frame(audio_window, FRAME_LEN_SAMPLES, mel_frame_out);

    // Pass natural log ln(x) from esp-dl Fbank directly to match PyTorch's torch.log()

    // Shift each Mel channel's time-series left by 1 frame and append the new Mel coefficient.
    // Memory layout is Freq-major [NUM_MEL_BINS, TIME_FRAMES] ([52, 313])
    for (int m = 0; m < NUM_MEL_BINS; m++) {
        float *row = sliding_window_buf + m * TIME_FRAMES;
        memmove(row, row + 1, (TIME_FRAMES - 1) * sizeof(float));
        row[TIME_FRAMES - 1] = mel_frame_out[m];
    }
    last_ap_end = k_cycle_get_32();
    gpio_pin_set_dt(&sync_ap, 0); /* Set AP pin Low */
    last_ap_time_ms = (double)(last_ap_end - last_ap_start) / (sys_clock_hw_cycles_per_sec() / 1000.0);

    if (frame_counter % INFERENCE_STRIDE == 0) {
        // Calculate audio frame RMS over 256 samples to check for sound activity
        int64_t win_sum_sq = 0;
        for (int i = 0; i < FRAME_LEN_SAMPLES; i++) {
            win_sum_sq += (int32_t)audio_window[i] * (int32_t)audio_window[i];
        }
        float win_rms = sqrtf((float)win_sum_sq / FRAME_LEN_SAMPLES);

        if (win_rms >= VOICE_ACTIVITY_RMS_THRESHOLD) {
            k_sem_give(&inf_sem);
        }
    }
}

void KWSInference::run_inference_now()
{
    gpio_pin_set_dt(&sync_inf, 1); /* Set INF pin High */
    last_inf_start = k_cycle_get_32();

    // Feed raw Log-Mel Spectrogram directly (matching PyTorch & Silicon Labs pipeline 1-to-1)
    dl::TensorBase float_sliding_tensor({1, NUM_MEL_BINS, TIME_FRAMES, 1}, 
                                        sliding_window_buf, 
                                        0, 
                                        dl::DATA_TYPE_FLOAT);

    input_tensor->assign(&float_sliding_tensor);
    model->reset(); // Reset GRU hidden states to zero to match PyTorch evaluation
    model->run();   // Run the neural network
    last_inf_end = k_cycle_get_32();
    gpio_pin_set_dt(&sync_inf, 0); /* Set INF pin Low */
    last_inf_time_ms = (double)(last_inf_end - last_inf_start) / (sys_clock_hw_cycles_per_sec() / 1000.0);

    int8_t *int8_logits = (int8_t *)output_tensor->data;
    float scale = DL_SCALE(output_tensor->exponent);

    float fp32_logits[NUM_CLASSES];
    for (int c = 0; c < NUM_CLASSES; c++) {
        fp32_logits[c] = int8_logits[c] * scale;
    }

    float probs[NUM_CLASSES] = {0.0f};
    compute_softmax(fp32_logits, probs, NUM_CLASSES);

    // EMA Temporal Probability Smoothing (alpha = 0.60: 60% current frame, 40% memory)
    static float smoothed_probs[NUM_CLASSES] = {0.0f};
    static bool is_first_run = true;
    const float alpha = 0.60f;

    if (is_first_run) {
        for (int c = 0; c < NUM_CLASSES; c++) {
            smoothed_probs[c] = probs[c];
        }
        is_first_run = false;
    } else {
        for (int c = 0; c < NUM_CLASSES; c++) {
            smoothed_probs[c] = alpha * probs[c] + (1.0f - alpha) * smoothed_probs[c];
        }
    }

    // Compute Top 3 predicted ESC-50 classes from smoothed probabilities
    int top_idx[3] = {0, 0, 0};
    float top_p[3] = {-1.0f, -1.0f, -1.0f};

    for (int c = 0; c < NUM_CLASSES; c++) {
        if (smoothed_probs[c] > top_p[0]) {
            top_p[2] = top_p[1]; top_idx[2] = top_idx[1];
            top_p[1] = top_p[0]; top_idx[1] = top_idx[0];
            top_p[0] = smoothed_probs[c]; top_idx[0] = c;
        } else if (smoothed_probs[c] > top_p[1]) {
            top_p[2] = top_p[1]; top_idx[2] = top_idx[1];
            top_p[1] = smoothed_probs[c]; top_idx[1] = c;
        } else if (smoothed_probs[c] > top_p[2]) {
            top_p[2] = smoothed_probs[c]; top_idx[2] = c;
        }
    }

    LOG_INF("ESC-50: #1 %s (%.1f%%) | #2 %s (%.1f%%) | #3 %s (%.1f%%) [Inf: %.2f ms | DSP: %.2f ms]",
            CLASS_LABELS[top_idx[0]], (double)(top_p[0] * 100.0f),
            CLASS_LABELS[top_idx[1]], (double)(top_p[1] * 100.0f),
            CLASS_LABELS[top_idx[2]], (double)(top_p[2] * 100.0f),
            last_inf_time_ms, last_ap_time_ms);
}
```

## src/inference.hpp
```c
/*
 * Copyright (c) 2026 Seeed Studio / Senior ML Engineer
 * SPDX-License-Identifier: Apache-2.0
 */

#ifndef INFERENCE_HPP
#define INFERENCE_HPP

#include "dl_model_base.hpp"
#include "dl_tensor_base.hpp"
#include "dl_fbank.hpp"
#include <zephyr/kernel.h>
#include <cstdint>

class KWSInference {
public:
    KWSInference();
    ~KWSInference();

    /**
     * @brief Initialize neural network model, Mel filterbank, and PSRAM sliding window buffer.
     * @return true on success, false on failure.
     */
    bool init();

    /**
     * @brief Process an audio frame (256 samples), extract Fbank features, update sliding window,
     * and run KWS inference every INFERENCE_STRIDE frames.
     * @param audio_window Array of 256 audio samples (int16_t).
     * @param frame_counter Current frame counter.
     * @param log_details Whether detailed frame logs should be printed.
     */
    void process_audio_window(const int16_t *audio_window, int frame_counter, bool log_details);

    /**
     * @brief Execute neural network inference on Core 1 in background thread.
     */
    void run_inference_now();

    struct k_sem inf_sem;

private:
    void compute_softmax(const float *logits, float *probs, int len);

    dl::Model *model;
    dl::audio::Fbank *fbank;
    dl::TensorBase *input_tensor;
    dl::TensorBase *output_tensor;
    float *sliding_window_buf;
    float *normalized_buf;
    int cooldown_counter;
    int last_detected_class;
    int consecutive_count;
    int dropout_count;

    // Timing diagnostic variables
    uint32_t last_ap_start;
    uint32_t last_ap_end;
    double last_ap_time_ms;

    uint32_t last_inf_start;
    uint32_t last_inf_end;
    double last_inf_time_ms;
};

#endif // INFERENCE_HPP
```
